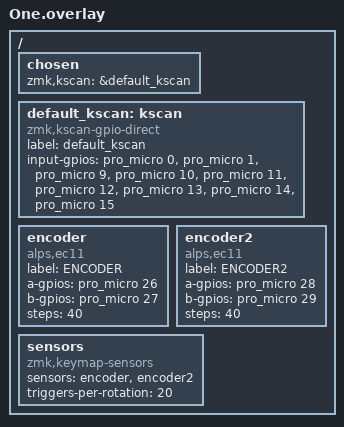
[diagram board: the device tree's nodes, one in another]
#include <rp2040_zero_connector.dtsi>

/ {
    chosen {
        zmk,kscan = &default_kscan;
    };

    default_kscan: kscan {
        compatible = "zmk,kscan-gpio-direct";
        label = "default_kscan";
        
        input-gpios =
            <&pro_micro 0 (GPIO_ACTIVE_HIGH | GPIO_PULL_DOWN)>,
            <&pro_micro 1 (GPIO_ACTIVE_HIGH | GPIO_PULL_DOWN)>,
            <&pro_micro 9 (GPIO_ACTIVE_HIGH | GPIO_PULL_DOWN)>,
            <&pro_micro 10 (GPIO_ACTIVE_HIGH | GPIO_PULL_DOWN)>,
            <&pro_micro 11 (GPIO_ACTIVE_HIGH | GPIO_PULL_DOWN)>,
            <&pro_micro 12 (GPIO_ACTIVE_HIGH | GPIO_PULL_DOWN)>,
            <&pro_micro 13 (GPIO_ACTIVE_HIGH | GPIO_PULL_DOWN)>,
            <&pro_micro 14 (GPIO_ACTIVE_HIGH | GPIO_PULL_DOWN)>,
            <&pro_micro 15 (GPIO_ACTIVE_HIGH | GPIO_PULL_DOWN)>;
    };

    encoder: encoder {
        compatible = "alps,ec11";
        label = "ENCODER";
        a-gpios = <&pro_micro 26 (GPIO_ACTIVE_HIGH | GPIO_PULL_UP)>;
        b-gpios = <&pro_micro 27 (GPIO_ACTIVE_HIGH | GPIO_PULL_UP)>;
        steps = <40>;
        status = "okay";
    };

    encoder2: encoder2 {
        compatible = "alps,ec11";
        label = "ENCODER2";
        a-gpios = <&pro_micro 28 (GPIO_ACTIVE_HIGH | GPIO_PULL_UP)>;
        b-gpios = <&pro_micro 29 (GPIO_ACTIVE_HIGH | GPIO_PULL_UP)>;
        steps = <40>;
        status = "okay";
    };

    sensors {
        compatible = "zmk,keymap-sensors";
        sensors = <&encoder &encoder2>;
        triggers-per-rotation = <20>;
    };
};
